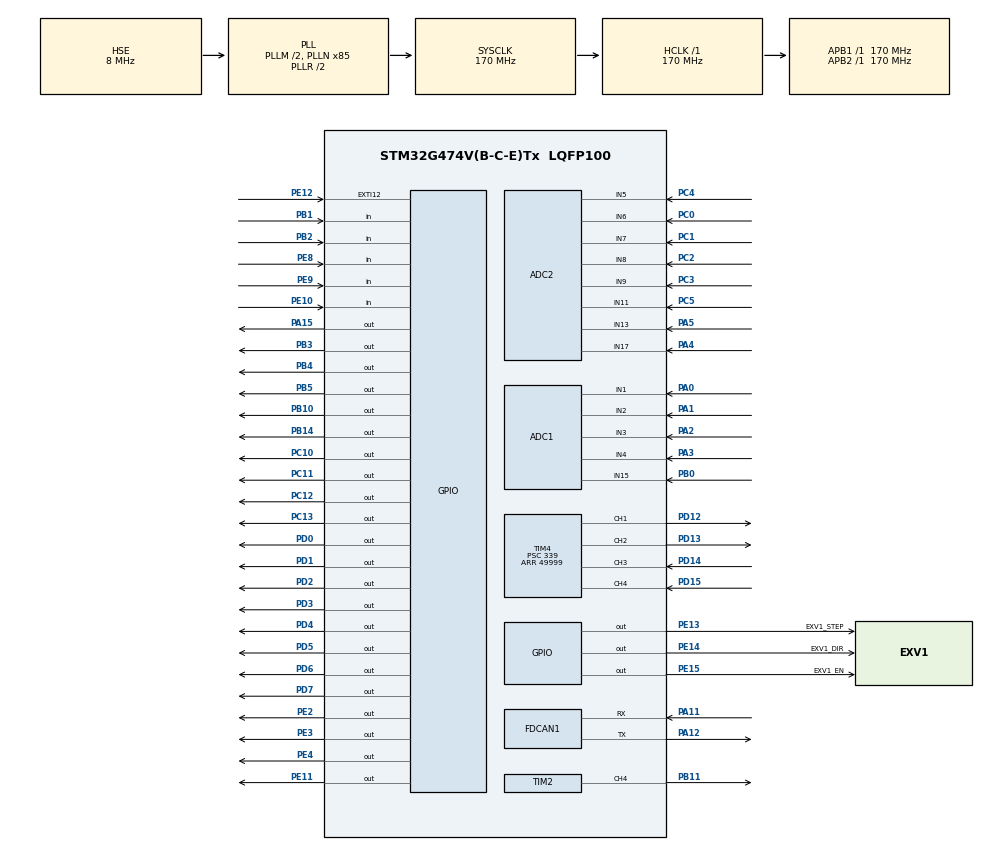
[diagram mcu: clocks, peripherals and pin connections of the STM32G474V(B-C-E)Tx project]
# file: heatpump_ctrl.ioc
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ADC1.Channel-0\#ChannelRegularConversion=ADC_CHANNEL_1
ADC1.Channel-1\#ChannelRegularConversion=ADC_CHANNEL_2
ADC1.Channel-2\#ChannelRegularConversion=ADC_CHANNEL_3
ADC1.Channel-3\#ChannelRegularConversion=ADC_CHANNEL_4
ADC1.Channel-4\#ChannelRegularConversion=ADC_CHANNEL_15
ADC1.ContinuousConvMode=ENABLE
ADC1.DMAContinuousRequests=ENABLE
ADC1.NbrOfConversion=5
ADC1.NbrOfConversionFlag=1
ADC1.OffsetNumber-0\#ChannelRegularConversion=ADC_OFFSET_NONE
ADC1.OffsetNumber-1\#ChannelRegularConversion=ADC_OFFSET_NONE
ADC1.OffsetNumber-2\#ChannelRegularConversion=ADC_OFFSET_NONE
ADC1.OffsetNumber-3\#ChannelRegularConversion=ADC_OFFSET_NONE
ADC1.OffsetNumber-4\#ChannelRegularConversion=ADC_OFFSET_NONE
ADC1.Rank-0\#ChannelRegularConversion=1
ADC1.Rank-1\#ChannelRegularConversion=2
ADC1.Rank-2\#ChannelRegularConversion=3
ADC1.Rank-3\#ChannelRegularConversion=4
ADC1.Rank-4\#ChannelRegularConversion=5
ADC1.SamplingTime-0\#ChannelRegularConversion=ADC_SAMPLETIME_47CYCLES_5
ADC1.SamplingTime-1\#ChannelRegularConversion=ADC_SAMPLETIME_47CYCLES_5
ADC1.SamplingTime-2\#ChannelRegularConversion=ADC_SAMPLETIME_47CYCLES_5
ADC1.SamplingTime-3\#ChannelRegularConversion=ADC_SAMPLETIME_47CYCLES_5
ADC1.SamplingTime-4\#ChannelRegularConversion=ADC_SAMPLETIME_47CYCLES_5
ADC1.master=1
ADC2.Channel-0\#ChannelRegularConversion=ADC_CHANNEL_17
ADC2.Channel-1\#ChannelRegularConversion=ADC_CHANNEL_13
ADC2.Channel-2\#ChannelRegularConversion=ADC_CHANNEL_6
ADC2.Channel-3\#ChannelRegularConversion=ADC_CHANNEL_7
ADC2.Channel-4\#ChannelRegularConversion=ADC_CHANNEL_8
ADC2.Channel-5\#ChannelRegularConversion=ADC_CHANNEL_9
ADC2.Channel-6\#ChannelRegularConversion=ADC_CHANNEL_5
ADC2.Channel-7\#ChannelRegularConversion=ADC_CHANNEL_11
ADC2.NbrOfConversion=8
ADC2.NbrOfConversionFlag=1
ADC2.OffsetNumber-0\#ChannelRegularConversion=ADC_OFFSET_NONE
ADC2.OffsetNumber-1\#ChannelRegularConversion=ADC_OFFSET_NONE
ADC2.OffsetNumber-2\#ChannelRegularConversion=ADC_OFFSET_NONE
ADC2.OffsetNumber-3\#ChannelRegularConversion=ADC_OFFSET_NONE
ADC2.OffsetNumber-4\#ChannelRegularConversion=ADC_OFFSET_NONE
ADC2.OffsetNumber-5\#ChannelRegularConversion=ADC_OFFSET_NONE
ADC2.OffsetNumber-6\#ChannelRegularConversion=ADC_OFFSET_NONE
ADC2.OffsetNumber-7\#ChannelRegularConversion=ADC_OFFSET_NONE
ADC2.Rank-0\#ChannelRegularConversion=1
ADC2.Rank-1\#ChannelRegularConversion=2
ADC2.Rank-2\#ChannelRegularConversion=3
ADC2.Rank-3\#ChannelRegularConversion=4
ADC2.Rank-4\#ChannelRegularConversion=5
ADC2.Rank-5\#ChannelRegularConversion=6
ADC2.Rank-6\#ChannelRegularConversion=7
ADC2.Rank-7\#ChannelRegularConversion=8
ADC2.SamplingTime-0\#ChannelRegularConversion=ADC_SAMPLETIME_47CYCLES_5
ADC2.SamplingTime-1\#ChannelRegularConversion=ADC_SAMPLETIME_47CYCLES_5
ADC2.SamplingTime-2\#ChannelRegularConversion=ADC_SAMPLETIME_47CYCLES_5
ADC2.SamplingTime-3\#ChannelRegularConversion=ADC_SAMPLETIME_47CYCLES_5
ADC2.SamplingTime-4\#ChannelRegularConversion=ADC_SAMPLETIME_47CYCLES_5
ADC2.SamplingTime-5\#ChannelRegularConversion=ADC_SAMPLETIME_47CYCLES_5
ADC2.SamplingTime-6\#ChannelRegularConversion=ADC_SAMPLETIME_47CYCLES_5
ADC2.SamplingTime-7\#ChannelRegularConversion=ADC_SAMPLETIME_47CYCLES_5
Dma.ADC1.0.Direction=DMA_PERIPH_TO_MEMORY
Dma.ADC1.0.EventEnable=DISABLE
Dma.ADC1.0.Instance=DMA1_Channel1
Dma.ADC1.0.MemDataAlignment=DMA_MDATAALIGN_HALFWORD
Dma.ADC1.0.MemInc=DMA_MINC_ENABLE
Dma.ADC1.0.Mode=DMA_CIRCULAR
Dma.ADC1.0.PeriphDataAlignment=DMA_PDATAALIGN_HALFWORD
Dma.ADC1.0.PeriphInc=DMA_PINC_DISABLE
Dma.ADC1.0.Polarity=HAL_DMAMUX_REQ_GEN_RISING
Dma.ADC1.0.Priority=DMA_PRIORITY_LOW
Dma.ADC1.0.RequestNumber=1
Dma.ADC1.0.SignalID=NONE
Dma.ADC1.0.SyncEnable=DISABLE
Dma.ADC1.0.SyncPolarity=HAL_DMAMUX_SYNC_NO_EVENT
Dma.ADC1.0.SyncRequestNumber=1
Dma.ADC1.0.SyncSignalID=NONE
Dma.ADC2.1.Direction=DMA_PERIPH_TO_MEMORY
Dma.ADC2.1.EventEnable=DISABLE
Dma.ADC2.1.Instance=DMA1_Channel2
Dma.ADC2.1.MemDataAlignment=DMA_MDATAALIGN_HALFWORD
Dma.ADC2.1.MemInc=DMA_MINC_ENABLE
Dma.ADC2.1.Mode=DMA_CIRCULAR
Dma.ADC2.1.PeriphDataAlignment=DMA_PDATAALIGN_HALFWORD
Dma.ADC2.1.PeriphInc=DMA_PINC_DISABLE
Dma.ADC2.1.Polarity=HAL_DMAMUX_REQ_GEN_RISING
Dma.ADC2.1.Priority=DMA_PRIORITY_LOW
Dma.ADC2.1.RequestNumber=1
Dma.ADC2.1.SignalID=NONE
Dma.ADC2.1.SyncEnable=DISABLE
Dma.ADC2.1.SyncPolarity=HAL_DMAMUX_SYNC_NO_EVENT
Dma.ADC2.1.SyncRequestNumber=1
Dma.ADC2.1.SyncSignalID=NONE
Dma.Request0=ADC1
Dma.Request1=ADC2
FDCAN1.CalculateBaudRateNominal=500000
FDCAN1.CalculateTimeBitNominal=2000
FDCAN1.CalculateTimeQuantumNominal=200.0
FDCAN1.NominalPrescaler=34
FDCAN1.NominalTimeSeg1=8
IWDG.Prescaler=IWDG_PRESCALER_64
IWDG.Reload=2499
Mcu.Family=STM32G4
Mcu.Name=STM32G474V(B-C-E)Tx
Mcu.Package=LQFP100
NVIC.DMA1_Channel1_IRQn=true\:4\:0\:true\:false\:true\:false\:true\:true
NVIC.DMA1_Channel2_IRQn=true\:4\:0\:true\:false\:true\:false\:true\:true
NVIC.FDCAN1_IT0_IRQn=true\:3\:0\:true\:false\:true\:true\:true\:true
NVIC.PriorityGroup=NVIC_PRIORITYGROUP_4
NVIC.TIM4_IRQn=true\:1\:0\:true\:false\:true\:true\:true\:true
NVIC.TIM6_DAC_IRQn=true\:0\:0\:false\:false\:true\:true\:true\:true
NVIC.TIM7_DAC_IRQn=true\:2\:0\:true\:false\:true\:true\:true\:true
NVIC.TIM8_UP_IRQn=true\:15\:0\:false\:false\:true\:false\:true\:true
NVIC.TimeBase=TIM8_UP_IRQn
NVIC.TimeBaseIP=TIM8
PA0.Mode=IN1-Single-Ended
PA0.Signal=ADC1_IN1
PA1.Mode=IN2-Single-Ended
PA1.Signal=ADC1_IN2
PA11.Mode=FDCAN_Activate
PA11.Signal=FDCAN1_RX
PA12.Mode=FDCAN_Activate
PA12.Signal=FDCAN1_TX
PA13.Mode=Serial_Wire
PA13.Signal=SYS_JTMS-SWDIO
PA14.Mode=Serial_Wire
PA14.Signal=SYS_JTCK-SWCLK
PA15.Signal=GPIO_Output
PA2.Mode=IN3-Single-Ended
PA2.Signal=ADC1_IN3
PA3.Mode=IN4-Single-Ended
PA3.Signal=ADC1_IN4
PA4.Mode=IN17-Single-Ended
PA4.Signal=ADC2_IN17
PA5.Mode=IN13-Single-Ended
PA5.Signal=ADC2_IN13
PB0.Mode=IN15-Single-Ended
PB0.Signal=ADC1_IN15
PB1.GPIO_PuPd=GPIO_PULLUP
PB1.Signal=GPIO_Input
PB10.Signal=GPIO_Output
PB11.Signal=S_TIM2_CH4
PB14.Signal=GPIO_Output
PB2.GPIO_PuPd=GPIO_PULLDOWN
PB2.Signal=GPIO_Input
PB3.Signal=GPIO_Output
PB4.GPIO_Speed=GPIO_SPEED_FREQ_HIGH
PB4.Signal=GPIO_Output
PB5.PinState=GPIO_PIN_SET
PB5.Signal=GPIO_Output
PC0.Mode=IN6-Single-Ended
PC0.Signal=ADC2_IN6
PC1.Mode=IN7-Single-Ended
PC1.Signal=ADC2_IN7
PC10.GPIO_Speed=GPIO_SPEED_FREQ_HIGH
PC10.Signal=GPIO_Output
PC11.PinState=GPIO_PIN_SET
PC11.Signal=GPIO_Output
PC12.Signal=GPIO_Output
PC13.Signal=GPIO_Output
PC2.Mode=IN8-Single-Ended
PC2.Signal=ADC2_IN8
PC3.Mode=IN9-Single-Ended
PC3.Signal=ADC2_IN9
PC4.Mode=IN5-Single-Ended
PC4.Signal=ADC2_IN5
PC5.Mode=IN11-Single-Ended
PC5.Signal=ADC2_IN11
PD0.GPIO_Speed=GPIO_SPEED_FREQ_HIGH
PD0.Signal=GPIO_Output
PD1.PinState=GPIO_PIN_SET
PD1.Signal=GPIO_Output
PD12.Signal=S_TIM4_CH1
PD13.Signal=S_TIM4_CH2
PD14.Signal=S_TIM4_CH3
PD15.Signal=S_TIM4_CH4
PD2.Signal=GPIO_Output
PD3.GPIO_Speed=GPIO_SPEED_FREQ_HIGH
PD3.Signal=GPIO_Output
PD4.PinState=GPIO_PIN_SET
PD4.Signal=GPIO_Output
PD5.Signal=GPIO_Output
PD6.GPIO_Speed=GPIO_SPEED_FREQ_HIGH
PD6.Signal=GPIO_Output
PD7.PinState=GPIO_PIN_SET
PD7.Signal=GPIO_Output
PE10.GPIO_PuPd=GPIO_PULLDOWN
PE10.Signal=GPIO_Input
PE11.Signal=GPIO_Output
PE12.GPIO_ModeDefaultEXTI=GPIO_MODE_IT_RISING_FALLING
PE12.GPIO_PuPd=GPIO_NOPULL
PE12.Signal=GPXTI12
PE13.GPIO_Label=EXV1_STEP
PE13.Signal=GPIO_Output
PE14.GPIO_Label=EXV1_DIR
PE14.Signal=GPIO_Output
PE15.GPIO_Label=EXV1_EN
PE15.PinState=GPIO_PIN_SET
PE15.Signal=GPIO_Output
PE2.Signal=GPIO_Output
PE3.GPIO_Speed=GPIO_SPEED_FREQ_HIGH
PE3.Signal=GPIO_Output
PE4.PinState=GPIO_PIN_SET
PE4.Signal=GPIO_Output
PE8.GPIO_PuPd=GPIO_PULLDOWN
PE8.Signal=GPIO_Input
PE9.GPIO_PuPd=GPIO_PULLDOWN
PE9.Signal=GPIO_Input
PF0-OSC_IN.Mode=HSE-External-Oscillator
PF0-OSC_IN.Signal=RCC_OSC_IN
PF1-OSC_OUT.Mode=HSE-External-Oscillator
PF1-OSC_OUT.Signal=RCC_OSC_OUT
ProjectManager.HeapSize=0x200
ProjectManager.StackSize=0x400
ProjectManager.TargetToolchain=STM32CubeIDE
RCC.ADC12Freq_Value=170000000
RCC.ADC345Freq_Value=170000000
RCC.AHBFreq_Value=170000000
RCC.APB1Freq_Value=170000000
RCC.APB1TimFreq_Value=170000000
RCC.APB2Freq_Value=170000000
RCC.APB2TimFreq_Value=170000000
RCC.CortexFreq_Value=170000000
RCC.EXTERNAL_CLOCK_VALUE=12288000
RCC.HCLKFreq_Value=170000000
RCC.HSE_VALUE=8000000
RCC.HSI48_VALUE=48000000
RCC.HSI_VALUE=16000000
RCC.LSE_VALUE=32768
RCC.PLLM=RCC_PLLM_DIV2
RCC.PLLN=85
RCC.PLLSourceVirtual=RCC_PLLSOURCE_HSE
RCC.SYSCLKFreq_VALUE=170000000
RCC.SYSCLKSource=RCC_SYSCLKSOURCE_PLLCLK
RCC.USBFreq_Value=170000000
RCC.VCOOutputFreq_Value=340000000
SH.S_TIM2_CH4.0=TIM2_CH4,PWM Generation4 CH4
SH.S_TIM4_CH1.0=TIM4_CH1,PWM Generation1 CH1
SH.S_TIM4_CH2.0=TIM4_CH2,PWM Generation2 CH2
SH.S_TIM4_CH3.0=TIM4_CH3,Input_Capture3_from_TI3
SH.S_TIM4_CH4.0=TIM4_CH4,Input_Capture4_from_TI4
TIM2.AutoReloadPreload=TIM_AUTORELOAD_PRELOAD_ENABLE
TIM2.Channel-PWM\ Generation4\ CH4=TIM_CHANNEL_4
TIM2.PeriodNoDither=65535
TIM2.Prescaler=25
TIM4.AutoReloadPreload=TIM_AUTORELOAD_PRELOAD_ENABLE
TIM4.Channel-Input_Capture3_from_TI3=TIM_CHANNEL_3
TIM4.Channel-Input_Capture4_from_TI4=TIM_CHANNEL_4
TIM4.Channel-PWM\ Generation1\ CH1=TIM_CHANNEL_1
TIM4.Channel-PWM\ Generation2\ CH2=TIM_CHANNEL_2
TIM4.PeriodNoDither=49999
TIM4.Prescaler=339
TIM6.AutoReloadPreload=TIM_AUTORELOAD_PRELOAD_ENABLE
TIM6.PeriodNoDither=999
TIM6.Prescaler=169
TIM7.AutoReloadPreload=TIM_AUTORELOAD_PRELOAD_ENABLE
TIM7.PeriodNoDither=999
TIM7.Prescaler=169
VP_IWDG_VS_IWDG.Mode=IWDG_Activate
VP_SYS_VS_DBSignals.Mode=DisableDeadBatterySignals
VP_SYS_VS_tim8.Mode=TIM8
VP_TIM6_VS_ClockSourceINT.Mode=Enable_Timer
VP_TIM7_VS_ClockSourceINT.Mode=Enable_Timer
board=custom

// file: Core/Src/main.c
/* USER CODE BEGIN Header */
/**
  ******************************************************************************
  * @file           : main.c
  * @brief          : Main program body
  ******************************************************************************
  * @attention
  *
  * Copyright (c) 2026 STMicroelectronics.
  * All rights reserved.
  *
  * This software is licensed under terms that can be found in the LICENSE file
  * in the root directory of this software component.
  * If no LICENSE file comes with this software, it is provided AS-IS.
  *
  ******************************************************************************
  */
/* USER CODE END Header */
#include "main.h"
#include "adc.h"
#include "dma.h"
#include "fdcan.h"
#include "iwdg.h"
#include "tim.h"
#include "gpio.h"

/* USER CODE BEGIN Includes */
#include "params.h"
#include "valves.h"
#include "sensors.h"
#include "pumps.h"
#include "can_comp.h"
#include "thermal_control.h"
/* USER CODE END Includes */

void SystemClock_Config(void);

int main(void)
{

  /* MCU Configuration--------------------------------------------------------*/

  /* Reset of all peripherals, Initializes the Flash interface and the Systick. */
  HAL_Init();

  /* Configure the system clock */
  SystemClock_Config();

  /* Initialize all configured peripherals */
  MX_GPIO_Init();
  MX_DMA_Init();
  MX_ADC1_Init();
  MX_FDCAN1_Init();
  MX_TIM2_Init();
  MX_TIM4_Init();
  MX_TIM6_Init();
  MX_TIM7_Init();
  MX_ADC2_Init();
  MX_IWDG_Init();
  /* USER CODE BEGIN 2 */
  App_Init();
  /* USER CODE END 2 */

  /* Infinite loop */
  while (1)
  {

  }
}

void SystemClock_Config(void)
{
  RCC_OscInitTypeDef RCC_OscInitStruct = {0};
  RCC_ClkInitTypeDef RCC_ClkInitStruct = {0};

  /** Configure the main internal regulator output voltage
  */
  HAL_PWREx_ControlVoltageScaling(PWR_REGULATOR_VOLTAGE_SCALE1_BOOST);

  /** Initializes the RCC Oscillators according to the specified parameters
  * in the RCC_OscInitTypeDef structure.
  */
  RCC_OscInitStruct.OscillatorType = RCC_OSCILLATORTYPE_LSI|RCC_OSCILLATORTYPE_HSE;
  RCC_OscInitStruct.HSEState = RCC_HSE_ON;
  RCC_OscInitStruct.LSIState = RCC_LSI_ON;
  RCC_OscInitStruct.PLL.PLLState = RCC_PLL_ON;
  RCC_OscInitStruct.PLL.PLLSource = RCC_PLLSOURCE_HSE;
  RCC_OscInitStruct.PLL.PLLM = RCC_PLLM_DIV2;
  RCC_OscInitStruct.PLL.PLLN = 85;
  RCC_OscInitStruct.PLL.PLLP = RCC_PLLP_DIV2;
  RCC_OscInitStruct.PLL.PLLQ = RCC_PLLQ_DIV2;
  RCC_OscInitStruct.PLL.PLLR = RCC_PLLR_DIV2;
  if (HAL_RCC_OscConfig(&RCC_OscInitStruct) != HAL_OK)
  {
    Error_Handler();
  }

  /** Initializes the CPU, AHB and APB buses clocks
  */
  RCC_ClkInitStruct.ClockType = RCC_CLOCKTYPE_HCLK|RCC_CLOCKTYPE_SYSCLK
                              |RCC_CLOCKTYPE_PCLK1|RCC_CLOCKTYPE_PCLK2;
  RCC_ClkInitStruct.SYSCLKSource = RCC_SYSCLKSOURCE_PLLCLK;
  RCC_ClkInitStruct.AHBCLKDivider = RCC_SYSCLK_DIV1;
  RCC_ClkInitStruct.APB1CLKDivider = RCC_HCLK_DIV1;
  RCC_ClkInitStruct.APB2CLKDivider = RCC_HCLK_DIV1;

  if (HAL_RCC_ClockConfig(&RCC_ClkInitStruct, FLASH_LATENCY_4) != HAL_OK)
  {
    Error_Handler();
  }
}

/* USER CODE BEGIN 4 */
/* NOTE: HAL_TIM_PeriodElapsedCallback is defined in app.c
 * Delete the generated version of this function every time
 * CubeMX regenerates main.c */
/* USER CODE END 4 */

void Error_Handler(void)
{
  __disable_irq();
  while (1)
  {
  }
}
